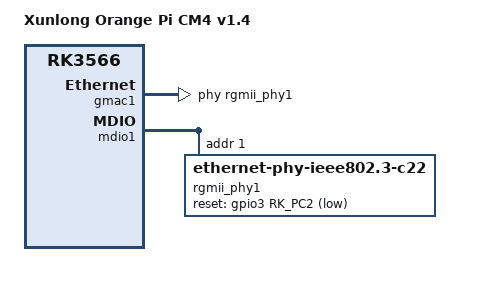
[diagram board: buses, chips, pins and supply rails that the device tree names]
// SPDX-License-Identifier: (GPL-2.0+ OR MIT)

/dts-v1/;

#include "rk3566-orangepi-cm4.dtsi"

/ {
	model = "Xunlong Orange Pi CM4 v1.4";
	compatible = "xunlong,orangepi-cm4-v1.4", "xunlong,orangepi-cm4", "rockchip,rk3566";
};

&pmu_io_domains {
	vccio5-supply = <&vcc_3v3>;
};

&gmac1 {
	phy-handle = <&rgmii_phy1>;
	status = "okay";
};

&mdio1 {
	rgmii_phy1: ethernet-phy@1 {
		compatible = "ethernet-phy-ieee802.3-c22";
		reg = <1>;
		reset-assert-us = <20000>;
		reset-deassert-us = <50000>;
		reset-gpios = <&gpio3 RK_PC2 GPIO_ACTIVE_LOW>;
	};
};
